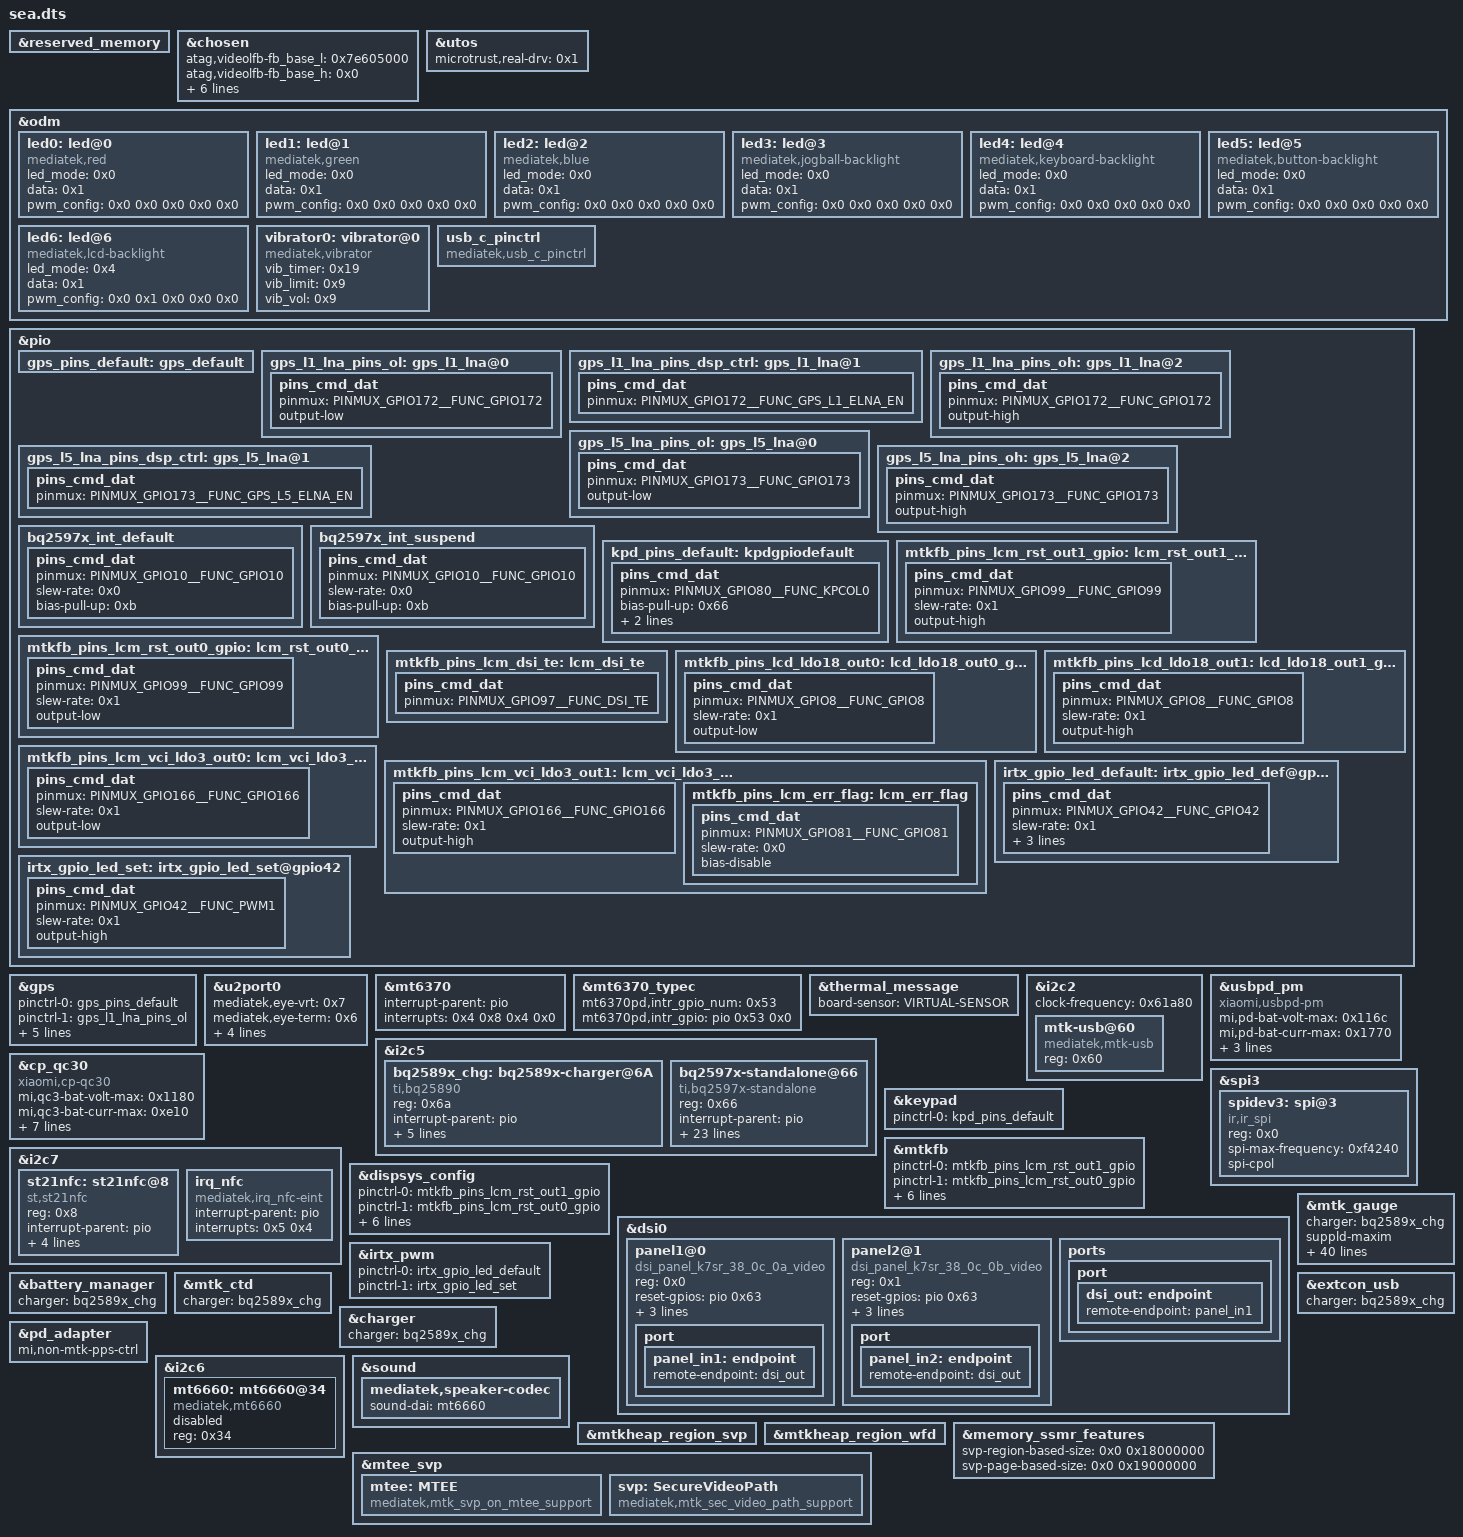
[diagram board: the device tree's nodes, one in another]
// SPDX-License-Identifier: GPL-2.0-only
/* Xiaomi Redmi Note 12S (sea / mt6781) Device Tree Overlay for Google Android Common Kernel 6.6 */

/dts-v1/;
/plugin/;

#include <dt-bindings/interrupt-controller/arm-gic.h>
#include <dt-bindings/interrupt-controller/irq.h>
#include <dt-bindings/pinctrl/mt6781-pinfunc.h>
#include <dt-bindings/gpio/gpio.h>
#include <dt-bindings/iio/mt635x-auxadc.h>

&reserved_memory {
};

&chosen {
    atag,videolfb-fb_base_l = <0x7e605000>;
    atag,videolfb-fb_base_h = <0x0>;
    atag,videolfb-islcmfound = <0x1>;
    atag,videolfb-islcm_inited = <0x0>;
    atag,videolfb-fps = <0x1770>;
    atag,videolfb-vramSize = <0x17e8000>;
    atag,videolfb-lcmname = "nt35695_fhd_dsi_cmd_truly_rt5081_drv";
};

&utos {
    microtrust,real-drv = <0x1>;
};

&odm {
    led0: led@0 {
        compatible = "mediatek,red";
        led_mode = <0x0>;
        data = <0x1>;
        pwm_config = <0x0 0x0 0x0 0x0 0x0>;
    };
    led1: led@1 {
        compatible = "mediatek,green";
        led_mode = <0x0>;
        data = <0x1>;
        pwm_config = <0x0 0x0 0x0 0x0 0x0>;
    };
    led2: led@2 {
        compatible = "mediatek,blue";
        led_mode = <0x0>;
        data = <0x1>;
        pwm_config = <0x0 0x0 0x0 0x0 0x0>;
    };
    led3: led@3 {
        compatible = "mediatek,jogball-backlight";
        led_mode = <0x0>;
        data = <0x1>;
        pwm_config = <0x0 0x0 0x0 0x0 0x0>;
    };
    led4: led@4 {
        compatible = "mediatek,keyboard-backlight";
        led_mode = <0x0>;
        data = <0x1>;
        pwm_config = <0x0 0x0 0x0 0x0 0x0>;
    };
    led5: led@5 {
        compatible = "mediatek,button-backlight";
        led_mode = <0x0>;
        data = <0x1>;
        pwm_config = <0x0 0x0 0x0 0x0 0x0>;
    };
    led6: led@6 {
        compatible = "mediatek,lcd-backlight";
        led_mode = <0x4>;
        data = <0x1>;
        pwm_config = <0x0 0x1 0x0 0x0 0x0>;
    };
    vibrator0: vibrator@0 {
        compatible = "mediatek,vibrator";
        vib_timer = <0x19>;
        vib_limit = <0x9>;
        vib_vol = <0x9>;
    };
    usb_c_pinctrl: usb_c_pinctrl {
        compatible = "mediatek,usb_c_pinctrl";
    };
};

&pio {
    gps_pins_default: gps_default {
    };
    gps_l1_lna_pins_ol: gps_l1_lna@0 {
        pins_cmd_dat {
            pinmux = <PINMUX_GPIO172__FUNC_GPIO172>;
            output-low;
        };
    };
    gps_l1_lna_pins_dsp_ctrl: gps_l1_lna@1 {
        pins_cmd_dat {
            pinmux = <PINMUX_GPIO172__FUNC_GPS_L1_ELNA_EN>;
        };
    };
    gps_l1_lna_pins_oh: gps_l1_lna@2 {
        pins_cmd_dat {
            pinmux = <PINMUX_GPIO172__FUNC_GPIO172>;
            output-high;
        };
    };
    gps_l5_lna_pins_ol: gps_l5_lna@0 {
        pins_cmd_dat {
            pinmux = <PINMUX_GPIO173__FUNC_GPIO173>;
            output-low;
        };
    };
    gps_l5_lna_pins_dsp_ctrl: gps_l5_lna@1 {
        pins_cmd_dat {
            pinmux = <PINMUX_GPIO173__FUNC_GPS_L5_ELNA_EN>;
        };
    };
    gps_l5_lna_pins_oh: gps_l5_lna@2 {
        pins_cmd_dat {
            pinmux = <PINMUX_GPIO173__FUNC_GPIO173>;
            output-high;
        };
    };
};

&gps {
    pinctrl-names = "default", "gps_l1_lna_disable", "gps_l1_lna_dsp_ctrl", "gps_l1_lna_enable", "gps_l5_lna_disable", "gps_l5_lna_dsp_ctrl", "gps_l5_lna_enable";
    pinctrl-0 = <&gps_pins_default>;
    pinctrl-1 = <&gps_l1_lna_pins_ol>;
    pinctrl-2 = <&gps_l1_lna_pins_dsp_ctrl>;
    pinctrl-3 = <&gps_l1_lna_pins_oh>;
    pinctrl-4 = <&gps_l5_lna_pins_ol>;
    pinctrl-5 = <&gps_l5_lna_pins_dsp_ctrl>;
    pinctrl-6 = <&gps_l5_lna_pins_oh>;
    status = "okay";
};

&u2port0 {
    mediatek,eye-vrt = <0x7>;
    mediatek,eye-term = <0x6>;
    mediatek,rev6 = <0x3>;
    mediatek,host-eye-vrt = <0x4>;
    mediatek,host-eye-term = <0x4>;
    mediatek,host-eye-rev6 = <0x1>;
};

&mt6370 {
    interrupt-parent = <&pio>;
    interrupts = <0x4 0x8 0x4 0x0>;
};

&mt6370_typec {
    mt6370pd,intr_gpio_num = <0x53>;
    mt6370pd,intr_gpio = <&pio 0x53 0x0>;
};

&thermal_message {
    board-sensor = "VIRTUAL-SENSOR";
};

&i2c2 {
    clock-frequency = <0x61a80>;
    mtk-usb@60 {
        compatible = "mediatek,mtk-usb";
        reg = <0x60>;
        status = "okay";
    };
};

&pio {
    bq2597x_int_default: bq2597x_int_default {
        pins_cmd_dat {
            pinmux = <PINMUX_GPIO10__FUNC_GPIO10>;
            slew-rate = <0x0>;
            bias-pull-up = <0xb>;
        };
    };
    bq2597x_int_suspend: bq2597x_int_suspend {
        pins_cmd_dat {
            pinmux = <PINMUX_GPIO10__FUNC_GPIO10>;
            slew-rate = <0x0>;
            bias-pull-up = <0xb>;
        };
    };
};

&i2c5 {
    status = "okay";
    bq2589x_chg: bq2589x-charger@6A {
        status = "okay";
        compatible = "ti,bq25890";
        reg = <0x6a>;
        interrupt-parent = <&pio>;
        interrupts = <0x1 0x2 0x1 0x0>;
        ti,irq-gpio = <&pio 0x1 0x0>;
        ti,bq2589x,charge-detect-enable;
        interrupt-names = "chr_stat";
        ti,CB1 = <&pio 0x2a 0x0>;
        ti,CB2 = <&pio 0x2b 0x0>;
    };
    bq2597x-standalone@66 {
        compatible = "ti,bq2597x-standalone";
        reg = <0x66>;
        interrupt-parent = <&pio>;
        interrupts = <0xa 0x2 0xa 0x0>;
        pinctrl-names = "chargerpump";
        pinctrl-0 = <&bq2597x_int_default &bq2597x_int_suspend>;
        ti,bq2597x,bat-ovp-alarm-disable;
        ti,bq2597x,bat-ucp-alarm-disable;
        ti,bq2597x,bat-ucp-disable;
        ti,bq2597x,bat-therm-disable;
        ti,bq2597x,bus-therm-disable;
        ti,bq2597x,die-therm-disable;
        ti,bq2597x,bat-ovp-threshold = <0x11ad>;
        ti,bq2597x,bat-ovp-alarm-threshold = <0x118a>;
        ti,bq2597x,bat-ocp-threshold = <0x1b58>;
        ti,bq2597x,bat-ocp-alarm-threshold = <0x1770>;
        ti,bq2597x,bus-ovp-threshold = <0x2ee0>;
        ti,bq2597x,bus-ovp-alarm-threshold = <0x2af8>;
        ti,bq2597x,bus-ocp-threshold = <0xea6>;
        ti,bq2597x,bus-ocp-alarm-threshold = <0xdac>;
        ti,bq2597x,bat-therm-threshold = <0x15>;
        ti,bq2597x,bus-therm-threshold = <0x15>;
        ti,bq2597x,die-therm-threshold = <0x91>;
        ti,bq2597x,ac-ovp-threshold = <0xe>;
        ti,bq2597x,sense-resistor-mohm = <0x5>;
        sc8551,ac-ovp-threshold = <0xd>;
    };
};

&usbpd_pm {
    compatible = "xiaomi,usbpd-pm";
    status = "okay";
    mi,pd-bat-volt-max = <0x116c>;
    mi,pd-bat-curr-max = <0x1770>;
    mi,pd-bus-volt-max = <0x2ee0>;
    mi,pd-bus-curr-max = <0xbb8>;
    mi,pd-non-ffc-bat-volt-max = <0x114e>;
};

&cp_qc30 {
    compatible = "xiaomi,cp-qc30";
    status = "okay";
    mi,qc3-bat-volt-max = <0x1180>;
    mi,qc3-bat-curr-max = <0xe10>;
    mi,qc3-bus-volt-max = <0x2ee0>;
    mi,qc3-bus-curr-max = <0x834>;
    mi,qc3-non-ffc-bat-volt-max = <0x1162>;
    mi,qc3-27w-bat-curr-max = <0x1518>;
    mi,qc3-27w-bus-curr-max = <0xa8c>;
    mi,qc3p-bat-curr-max = <0x1194>;
    mi,qc3p-bus-curr-max = <0x8fc>;
};

&spi3 {
    status = "okay";
    spidev3: spi@3 {
        compatible = "ir,ir_spi";
        reg = <0x0>;
        spi-max-frequency = <0xf4240>;
        spi-cpol;
    };
};

&i2c7 {
    st21nfc: st21nfc@8 {
        compatible = "st,st21nfc";
        reg = <0x8>;
        interrupt-parent = <&pio>;
        interrupts = <0x5 0x0>;
        reset-gpios = <&pio 0x1f 0x0>;
        irq-gpios = <&pio 0x5 0x0>;
        clkreq-gpios = <&pio 0x52 0x0>;
        status = "ok";
    };
    irq_nfc: irq_nfc {
        compatible = "mediatek,irq_nfc-eint";
        interrupt-parent = <&pio>;
        interrupts = <0x5 0x4>;
        status = "okay";
    };
};

&keypad {
    pinctrl-names = "default";
    pinctrl-0 = <&kpd_pins_default>;
};

&pio {
    kpd_pins_default: kpdgpiodefault {
        pins_cmd_dat {
            pinmux = <PINMUX_GPIO80__FUNC_KPCOL0>;
            bias-pull-up = <0x66>;
            input-enable;
            input-schmitt-enable;
        };
    };
};

&pio {
    mtkfb_pins_lcm_rst_out1_gpio: lcm_rst_out1_gpio {
        pins_cmd_dat {
            pinmux = <PINMUX_GPIO99__FUNC_GPIO99>;
            slew-rate = <0x1>;
            output-high;
        };
    };
    mtkfb_pins_lcm_rst_out0_gpio: lcm_rst_out0_gpio {
        pins_cmd_dat {
            pinmux = <PINMUX_GPIO99__FUNC_GPIO99>;
            slew-rate = <0x1>;
            output-low;
        };
    };
    mtkfb_pins_lcm_dsi_te: lcm_dsi_te {
        pins_cmd_dat {
            pinmux = <PINMUX_GPIO97__FUNC_DSI_TE>;
        };
    };
    mtkfb_pins_lcd_ldo18_out0: lcd_ldo18_out0_gpio {
        pins_cmd_dat {
            pinmux = <PINMUX_GPIO8__FUNC_GPIO8>;
            slew-rate = <0x1>;
            output-low;
        };
    };
    mtkfb_pins_lcd_ldo18_out1: lcd_ldo18_out1_gpio {
        pins_cmd_dat {
            pinmux = <PINMUX_GPIO8__FUNC_GPIO8>;
            slew-rate = <0x1>;
            output-high;
        };
    };
    mtkfb_pins_lcm_vci_ldo3_out0: lcm_vci_ldo3_out0_gpio {
        pins_cmd_dat {
            pinmux = <PINMUX_GPIO166__FUNC_GPIO166>;
            slew-rate = <0x1>;
            output-low;
        };
    };
    mtkfb_pins_lcm_vci_ldo3_out1: lcm_vci_ldo3_out1_gpio {
        pins_cmd_dat {
            pinmux = <PINMUX_GPIO166__FUNC_GPIO166>;
            slew-rate = <0x1>;
            output-high;
        };
        mtkfb_pins_lcm_err_flag: lcm_err_flag {
            pins_cmd_dat {
                pinmux = <PINMUX_GPIO81__FUNC_GPIO81>;
                slew-rate = <0x0>;
                bias-disable;
            };
        };
    };
};

&mtkfb {
    pinctrl-names = "lcm_rst_out1_gpio", "lcm_rst_out0_gpio", "mode_te_te", "lcd_ldo18_out1_gpio", "lcd_ldo18_out0_gpio", "lcm_vci_ldo3_out1_gpio", "lcm_vci_ldo3_out0_gpio", "err_flag_init";
    pinctrl-0 = <&mtkfb_pins_lcm_rst_out1_gpio>;
    pinctrl-1 = <&mtkfb_pins_lcm_rst_out0_gpio>;
    pinctrl-2 = <&mtkfb_pins_lcm_dsi_te>;
    pinctrl-3 = <&mtkfb_pins_lcd_ldo18_out1>;
    pinctrl-4 = <&mtkfb_pins_lcd_ldo18_out0>;
    pinctrl-7 = <&mtkfb_pins_lcm_vci_ldo3_out1>;
    pinctrl-8 = <&mtkfb_pins_lcm_vci_ldo3_out0>;
    pinctrl-9 = <&mtkfb_pins_lcm_err_flag>;
    status = "okay";
};

&dispsys_config {
    pinctrl-names = "lcm_rst_out1_gpio", "lcm_rst_out0_gpio", "mode_te_te", "lcd_ldo18_out1_gpio", "lcd_ldo18_out0_gpio", "lcm_vci_ldo3_out1_gpio", "lcm_vci_ldo3_out0_gpio", "err_flag_init";
    pinctrl-0 = <&mtkfb_pins_lcm_rst_out1_gpio>;
    pinctrl-1 = <&mtkfb_pins_lcm_rst_out0_gpio>;
    pinctrl-2 = <&mtkfb_pins_lcm_dsi_te>;
    pinctrl-3 = <&mtkfb_pins_lcd_ldo18_out1>;
    pinctrl-4 = <&mtkfb_pins_lcd_ldo18_out0>;
    pinctrl-7 = <&mtkfb_pins_lcm_vci_ldo3_out1>;
    pinctrl-8 = <&mtkfb_pins_lcm_vci_ldo3_out0>;
    pinctrl-9 = <&mtkfb_pins_lcm_err_flag>;
    status = "okay";
};

&dsi0 {
    status = "okay";
    #address-cells = <0x1>;
    #size-cells = <0x0>;
    panel1@0 {
        compatible = "dsi_panel_k7sr_38_0c_0a_video";
        reg = <0x0>;
        reset-gpios = <&pio 0x63 0x0>;
        vci-gpios = <&pio 0xa6 0x0>;
        vddi-gpios = <&pio 0x8 0x0>;
        mi,esd-err-irq-gpio = <&pio 0x51 0x2002>;
        pinctrl-names = "default";
        port {
            panel_in1: endpoint {
                remote-endpoint = <&dsi_out>;
            };
        };
    };
    panel2@1 {
        compatible = "dsi_panel_k7sr_38_0c_0b_video";
        reg = <0x1>;
        reset-gpios = <&pio 0x63 0x0>;
        vci-gpios = <&pio 0xa6 0x0>;
        vddi-gpios = <&pio 0x8 0x0>;
        mi,esd-err-irq-gpio = <&pio 0x51 0x2001>;
        pinctrl-names = "default";
        port {
            panel_in2: endpoint {
                remote-endpoint = <&dsi_out>;
            };
        };
    };
    ports {
        port {
            dsi_out: endpoint {
                remote-endpoint = <&panel_in1>;
            };
        };
    };
};

&irtx_pwm {
    pinctrl-names = "irtx_gpio_led_default", "irtx_gpio_led_set";
    pinctrl-0 = <&irtx_gpio_led_default>;
    pinctrl-1 = <&irtx_gpio_led_set>;
    status = "okay";
};

&pio {
    irtx_gpio_led_default: irtx_gpio_led_def@gpio42 {
        pins_cmd_dat {
            pinmux = <PINMUX_GPIO42__FUNC_GPIO42>;
            slew-rate = <0x1>;
            bias-disable;
            output-low;
            input-schmitt-enable = <0x0>;
        };
    };
    irtx_gpio_led_set: irtx_gpio_led_set@gpio42 {
        pins_cmd_dat {
            pinmux = <PINMUX_GPIO42__FUNC_PWM1>;
            slew-rate = <0x1>;
            output-high;
        };
    };
};

&mtk_gauge {
    charger = <&bq2589x_chg>;
    suppld-maxim;
    battery0_profile_t0_num = <0x64>;
    battery0_profile_t0_col = <0x3>;
    battery0_profile_t0 = <0x0 0xac94 0x1e0 0x1fd 0xabfb 0x1dc 0x3fa 0xab78 0x1ec 0x5f7 0xaafe 0x1f4 0x7f4 0xaa87 0x1ea 0x9f0 0xaa15 0x1e7 0xbed 0xa9ae 0x20b 0xdea 0xa937 0x1f6 0xfe7 0xa8c0 0x1f4 0x11e4 0xa849 0x1f4 0x13e1 0xa7d3 0x1f4 0x15de 0xa75c 0x1fc 0x17db 0xa6e3 0x209 0x19d8 0xa664 0x1f5 0x1bd4 0xa5ee 0x20a 0x1dd1 0xa570 0x1fb 0x1fce 0xa4f0 0x1f4 0x21cb 0xa475 0x1f4 0x23c8 0xa3fe 0x1fb 0x25c5 0xa386 0x20d 0x27c2 0xa30f 0x20d 0x29bf 0xa290 0x1f8 0x2bbc 0xa21e 0x205 0x2db8 0xa1ab 0x21a 0x2fb5 0xa134 0x21d 0x31b2 0xa0bf 0x20d 0x33af 0xa050 0x20d 0x35ac 0x9fda 0x20d 0x37a9 0x9f72 0x220 0x39a6 0x9f06 0x226 0x3ba3 0x9e9d 0x232 0x3da0 0x9e34 0x237 0x3f9c 0x9dc9 0x22a 0x4199 0x9d6b 0x23f 0x4396 0x9d06 0x23f 0x4593 0x9ca7 0x251 0x4790 0x9c4a 0x258 0x498d 0x9bf0 0x26c 0x4b8a 0x9b96 0x284 0x4d87 0x9b32 0x276 0x4f84 0x9ad4 0x2a0 0x5180 0x9a67 0x2a3 0x537d 0x99df 0x273 0x557a 0x994f 0x240 0x5777 0x98cc 0x215 0x5974 0x9864 0x1f4 0x5b71 0x980f 0x1f4 0x5d6e 0x97c3 0x1f4 0x5f6b 0x9785 0x206 0x6168 0x9744 0x20d 0x6364 0x9704 0x20d 0x6561 0x96c9 0x20d 0x675e 0x968e 0x20a 0x695b 0x9652 0x1f5 0x6b58 0x961e 0x1f4 0x6d55 0x95eb 0x205 0x6f52 0x95be 0x20d 0x714f 0x958f 0x204 0x734c 0x955f 0x1fa 0x7548 0x9534 0x20d 0x7745 0x950a 0x20d 0x7942 0x94e7 0x20d 0x7b3f 0x94bf 0x20d 0x7d3c 0x9499 0x219 0x7f39 0x9477 0x226 0x8136 0x9455 0x22a 0x8333 0x9434 0x23f 0x8530 0x9412 0x23f 0x872c 0x93e9 0x251 0x8929 0x93a2 0x22e 0x8b26 0x9352 0x20d 0x8d23 0x930a 0x207 0x8f20 0x92d1 0x1f7 0x911d 0x92a7 0x20c 0x931a 0x9274 0x20d 0x9517 0x923b 0x1fd 0x9714 0x9209 0x200 0x9910 0x91df 0x204 0x9b0d 0x91b6 0x1f9 0x9d0a 0x9193 0x20c 0x9f07 0x9158 0x1f7 0xa104 0x9115 0x1f4 0xa301 0x90d7 0x203 0xa4fe 0x909c 0x20d 0xa6fb 0x9058 0x20d 0xa8f8 0x9008 0x20a 0xaaf4 0x8fd6 0x1f5 0xacf1 0x8fcc 0x209 0xaeee 0x8fbd 0x1fc 0xb0eb 0x8fb1 0x20e 0xb2e8 0x8f9d 0x226 0xb4e5 0x8f66 0x226 0xb6e2 0x8edf 0x226 0xb8df 0x8d6a 0x226 0xbadc 0x8b71 0x24d 0xbcd8 0x88d6 0x296 0xbed5 0x851d 0x31a 0xc0d2 0x7e46 0x991 0xc2cf 0x7084 0x7db 0xc4cc 0x6fa4 0x5dc>;
    battery0_profile_t1_num = <0x64>;
    battery0_profile_t1_col = <0x3>;
    battery0_profile_t1 = <0x0 0xacbc 0x30c 0x1fd 0xac3d 0x308 0x3fa 0xabcb 0x318 0x5f7 0xab5d 0x312 0x7f4 0xaaf3 0x311 0x9f0 0xaa8b 0x31a 0xbed 0xaa1c 0x307 0xdea 0xa9ae 0x307 0xfe7 0xa940 0x307 0x11e4 0xa8cb 0x307 0x13e1 0xa855 0x307 0x15de 0xa7db 0x2ff 0x17db 0xa75d 0x2f2 0x19d8 0xa6e6 0x306 0x1bd4 0xa667 0x2f1 0x1dd1 0xa5ef 0x300 0x1fce 0xa572 0x307 0x21cb 0xa4f3 0x2fd 0x23c8 0xa476 0x2f5 0x25c5 0xa3fe 0x307 0x27c2 0xa387 0x307 0x29bf 0xa308 0x307 0x2bbc 0xa296 0x318 0x2db8 0xa223 0x320 0x2fb5 0xa1ac 0x320 0x31b2 0xa135 0x320 0x33af 0xa0bf 0x322 0x35ac 0xa051 0x337 0x37a9 0x9fe3 0x339 0x39a6 0x9f74 0x339 0x3ba3 0x9f06 0x345 0x3da0 0x9e9b 0x352 0x3f9c 0x9e35 0x356 0x4199 0x9dcf 0x36b 0x4396 0x9d6a 0x380 0x4593 0x9d0b 0x396 0x4790 0x9ca8 0x3ab 0x498d 0x9c46 0x3c0 0x4b8a 0x9be6 0x3d5 0x4d87 0x9b81 0x3e8 0x4f84 0x9b1b 0x3e8 0x5180 0x9aad 0x3d4 0x537d 0x9a32 0x3af 0x557a 0x99ae 0x378 0x5777 0x992d 0x341 0x5974 0x98ba 0x317 0x5b71 0x9855 0x2ed 0x5d6e 0x9800 0x2d8 0x5f6b 0x97b3 0x2d5 0x6168 0x976c 0x2c7 0x6364 0x972c 0x2c7 0x6561 0x96f1 0x2d5 0x675e 0x96b7 0x2d8 0x695b 0x9684 0x2ed 0x6b58 0x9648 0x2d9 0x6d55 0x961a 0x2e6 0x6f52 0x95ea 0x2e1 0x714f 0x95bb 0x2de 0x734c 0x958e 0x2ee 0x7548 0x955c 0x2ee 0x7745 0x9532 0x2ee 0x7942 0x950f 0x2ee 0x7b3f 0x94ed 0x2fd 0x7d3c 0x94c7 0x2fb 0x7f39 0x94a3 0x2fe 0x8136 0x9487 0x320 0x8333 0x9466 0x320 0x8530 0x9444 0x320 0x872c 0x9422 0x320 0x8929 0x9400 0x320 0x8b26 0x93d6 0x316 0x8d23 0x93a5 0x301 0x8f20 0x937b 0x2ee 0x911d 0x9351 0x2ee 0x931a 0x931e 0x2da 0x9517 0x92eb 0x2c5 0x9714 0x92bd 0x2bc 0x9910 0x9296 0x2c5 0x9b0d 0x9274 0x2d5 0x9d0a 0x9252 0x2d5 0x9f07 0x921f 0x2d5 0xa104 0x91e5 0x2c3 0xa301 0x91a9 0x2cb 0xa4fe 0x916e 0x2d5 0xa6fb 0x9130 0x2d5 0xa8f8 0x90e9 0x2d8 0xaaf4 0x9095 0x2ed 0xacf1 0x9069 0x2d9 0xaeee 0x9053 0x2d5 0xb0eb 0x9047 0x2e2 0xb2e8 0x903a 0x301 0xb4e5 0x9025 0x320 0xb6e2 0x8ffb 0x322 0xb8df 0x8f84 0x337 0xbadc 0x8e15 0x339 0xbcd8 0x8c12 0x368 0xbed5 0x895e 0x3b3 0xc0d2 0x8571 0x450 0xc2cf 0x7e79 0x8d4 0xc4cc 0x726a 0xccb>;
    battery0_profile_t2_num = <0x64>;
    battery0_profile_t2_col = <0x3>;
    battery0_profile_t2 = <0x0 0xacc6 0x596 0x1fd 0xac3e 0x592 0x3fa 0xabcb 0x5a2 0x5f7 0xab5d 0x59c 0x7f4 0xaaf3 0x591 0x9f0 0xaa8d 0x58b 0xbed 0xaa26 0x576 0xdea 0xa9b8 0x561 0xfe7 0xa94a 0x573 0x11e4 0xa8d5 0x558 0x13e1 0xa85f 0x546 0x15de 0xa7e5 0x536 0x17db 0xa767 0x518 0x19d8 0xa6f0 0x52c 0x1bd4 0xa671 0x517 0x1dd1 0xa5f2 0x514 0x1fce 0xa578 0x522 0x21cb 0xa4fd 0x523 0x23c8 0xa480 0x51b 0x25c5 0xa406 0x52a 0x27c2 0xa387 0x515 0x29bf 0xa310 0x529 0x2bbc 0xa299 0x52d 0x2db8 0xa223 0x52d 0x2fb5 0xa1ac 0x536 0x31b2 0xa137 0x54c 0x33af 0xa0c8 0x55f 0x35ac 0xa052 0x55f 0x37a9 0x9fe3 0x572 0x39a6 0x9f74 0x578 0x3ba3 0x9f0b 0x584 0x3da0 0x9ea5 0x5a0 0x3f9c 0x9e3e 0x5c3 0x4199 0x9dcf 0x5c3 0x4396 0x9d61 0x5d8 0x4593 0x9cfa 0x5ee 0x4790 0x9c94 0x5e7 0x498d 0x9c32 0x5e6 0x4b8a 0x9bd2 0x5f5 0x4d87 0x9b6d 0x5f5 0x4f84 0x9b07 0x5f5 0x5180 0x9a89 0x5ba 0x537d 0x9a0a 0x57a 0x557a 0x9986 0x52e 0x5777 0x9908 0x4ea 0x5974 0x989c 0x4c0 0x5b71 0x9837 0x496 0x5d6e 0x97e2 0x481 0x5f6b 0x979c 0x47e 0x6168 0x9758 0x47e 0x6364 0x9714 0x47e 0x6561 0x96d3 0x47e 0x675e 0x9699 0x47e 0x695b 0x9666 0x47e 0x6b58 0x9632 0x493 0x6d55 0x95f8 0x486 0x6f52 0x95c8 0x48b 0x714f 0x9599 0x497 0x734c 0x9569 0x497 0x7548 0x953e 0x497 0x7745 0x9514 0x497 0x7942 0x94f1 0x4aa 0x7b3f 0x94c9 0x4b0 0x7d3c 0x94a3 0x4b0 0x7f39 0x9481 0x4b8 0x8136 0x945f 0x4c9 0x8333 0x943e 0x4c9 0x8530 0x9424 0x4de 0x872c 0x9404 0x4d0 0x8929 0x93e7 0x4d7 0x8b26 0x93ca 0x4d8 0x8d23 0x93aa 0x4c9 0x8f20 0x9390 0x4c6 0x911d 0x936e 0x4b1 0x931a 0x934c 0x4b0 0x9517 0x9324 0x4b0 0x9714 0x92f4 0x4a4 0x9910 0x92c8 0x4a0 0x9b0d 0x92a5 0x4b0 0x9d0a 0x927a 0x4b1 0x9f07 0x9250 0x4c6 0xa104 0x920f 0x4db 0xa301 0x91cb 0x4e2 0xa4fe 0x918c 0x4ed 0xa6fb 0x914e 0x509 0xa8f8 0x9106 0x530 0xaaf4 0x90a9 0x545 0xacf1 0x907d 0x55b 0xaeee 0x9060 0x581 0xb0eb 0x904b 0x5b9 0xb2e8 0x9037 0x5ef 0xb4e5 0x9018 0x631 0xb6e2 0x8fe7 0x6b4 0xb8df 0x8f70 0x75e 0xbadc 0x8e18 0x7a6 0xbcd8 0x8c16 0x824 0xbed5 0x8955 0x952 0xc0d2 0x854d 0xbfa 0xc2cf 0x7e49 0x12cc 0xc4cc 0x7152 0x9dd>;
    battery0_profile_t3_num = <0x64>;
    battery0_profile_t3_col = <0x3>;
    battery0_profile_t3 = <0x0 0xace4 0x834 0x1fd 0xac54 0x834 0x3fa 0xabd2 0x9d6 0x5f7 0xab5d 0xaa7 0x7f4 0xaaf3 0xab4 0x9f0 0xaa8b 0xa99 0xbed 0xaa1d 0xa71 0xdea 0xa9b8 0xa5c 0xfe7 0xa942 0xa1f 0x11e4 0xa8d2 0xa0f 0x13e1 0xa85f 0xa03 0x15de 0xa7e5 0x9ee 0x17db 0xa767 0x9dd 0x19d8 0xa6f0 0x9dc 0x1bd4 0xa67a 0x9c7 0x1dd1 0xa5fc 0x9b2 0x1fce 0xa57c 0x99d 0x21cb 0xa501 0x992 0x23c8 0xa48a 0x984 0x25c5 0xa412 0x95d 0x27c2 0xa39b 0x948 0x29bf 0xa324 0x947 0x2bbc 0xa2a7 0x925 0x2db8 0xa232 0x922 0x2fb5 0xa1c0 0x925 0x31b2 0xa149 0x915 0x33af 0xa0d3 0x915 0x35ac 0xa065 0x915 0x37a9 0x9fef 0x902 0x39a6 0x9f84 0x90b 0x3ba3 0x9f1f 0x92c 0x3da0 0x9eb6 0x94f 0x3f9c 0x9e46 0x960 0x4199 0x9dcf 0x960 0x4396 0x9d61 0x975 0x4593 0x9cec 0x956 0x4790 0x9c7b 0x939 0x498d 0x9c10 0x924 0x4b8a 0x9ba8 0x909 0x4d87 0x9b3a 0x8de 0x4f84 0x9acb 0x8b4 0x5180 0x9a55 0x889 0x537d 0x99df 0x84f 0x557a 0x9968 0x803 0x5777 0x98f8 0x7c8 0x5974 0x9892 0x7ae 0x5b71 0x982d 0x784 0x5d6e 0x97e1 0x76f 0x5f6b 0x978d 0x75a 0x6168 0x9744 0x753 0x6364 0x9704 0x75e 0x6561 0x96c6 0x765 0x675e 0x9685 0x756 0x695b 0x9652 0x76b 0x6b58 0x9616 0x76c 0x6d55 0x95e1 0x77d 0x6f52 0x95ae 0x785 0x714f 0x957f 0x78e 0x734c 0x9552 0x79e 0x7548 0x9520 0x79e 0x7745 0x94f6 0x79e 0x7942 0x94d3 0x7c5 0x7b3f 0x94ab 0x7d0 0x7d3c 0x9485 0x7dc 0x7f39 0x9463 0x7f1 0x8136 0x9441 0x802 0x8333 0x9420 0x802 0x8530 0x9406 0x817 0x872c 0x93e6 0x81b 0x8929 0x93cf 0x81b 0x8b26 0x93be 0x82f 0x8d23 0x93ad 0x85a 0x8f20 0x939b 0x87f 0x911d 0x9382 0x87f 0x931a 0x9360 0x8a7 0x9517 0x933e 0x8c1 0x9714 0x9317 0x8e3 0x9910 0x92f0 0x916 0x9b0d 0x92cb 0x955 0x9d0a 0x9298 0x996 0x9f07 0x9265 0x9eb 0xa104 0x9223 0xa2d 0xa301 0x91df 0xa8a 0xa4fe 0x919c 0xaf4 0xa6fb 0x9155 0xb65 0xa8f8 0x9107 0xbe4 0xaaf4 0x90b3 0xc63 0xacf1 0x9076 0xd0b 0xaeee 0x9048 0xdc6 0xb0eb 0x9023 0xeae 0xb2e8 0x9001 0xfcc 0xb4e5 0x8fd8 0x1121 0xb6e2 0x8f95 0x12be 0xb8df 0x8f0e 0x14bb 0xbadc 0x8df2 0x16de 0xbcd8 0x8c34 0x19f0 0xbed5 0x89bb 0x1f51 0xc0d2 0x864d 0x2a26 0xc2cf 0x8163 0x3210 0xc4cc 0x7828 0x1b58>;
    battery0_profile_t4_num = <0x64>;
    battery0_profile_t4_col = <0x3>;
    battery0_profile_t4 = <0x0 0xacda 0x13d8 0x1fd 0xac1f 0x13d4 0x3fa 0xab88 0x13e4 0x5f7 0xab02 0x13de 0x7f4 0xaa83 0x13c9 0x9f0 0xaa04 0x13c6 0xbed 0xa986 0x13e8 0xdea 0xa90f 0x13bd 0xfe7 0xa898 0x137f 0x11e4 0xa821 0x1310 0x13e1 0xa7ab 0x129d 0x15de 0xa734 0x123b 0x17db 0xa6bd 0x11f4 0x19d8 0xa646 0x11df 0x1bd4 0xa5c7 0x11df 0x1dd1 0xa54f 0x11cd 0x1fce 0xa4d2 0x11b8 0x21cb 0xa45c 0x11ad 0x23c8 0xa3e7 0x119f 0x25c5 0xa369 0x117b 0x27c2 0xa2fb 0x117b 0x29bf 0xa284 0x1166 0x2bbc 0xa20d 0x1140 0x2db8 0xa19c 0x1123 0x2fb5 0xa12a 0x10fb 0x31b2 0xa0b5 0x10cc 0x33af 0xa047 0x10cc 0x35ac 0x9fd9 0x10cc 0x37a9 0x9f72 0x1105 0x39a6 0x9f00 0x1117 0x3ba3 0x9e89 0x1123 0x3da0 0x9e10 0x1128 0x3f9c 0x9d8f 0x110f 0x4199 0x9d07 0x10e5 0x4396 0x9c88 0x10ba 0x4593 0x9c10 0x1090 0x4790 0x9b99 0x1066 0x498d 0x9b26 0x103b 0x4b8a 0x9aba 0x101d 0x4d87 0x9a54 0x101b 0x4f84 0x99e5 0x1005 0x5180 0x9977 0xfdc 0x537d 0x990f 0xfe2 0x557a 0x98aa 0xfdf 0x5777 0x9847 0xfca 0x5974 0x97ee 0xfbe 0x5b71 0x97a1 0xfd2 0x5d6e 0x974c 0xfd2 0x5f6b 0x9706 0xfd2 0x6168 0x96c2 0xfd2 0x6364 0x967e 0xfdd 0x6561 0x9640 0xff2 0x675e 0x960c 0x1007 0x695b 0x95d0 0x101c 0x6b58 0x959c 0x1032 0x6d55 0x9569 0x1047 0x6f52 0x9536 0x105c 0x714f 0x9507 0x1071 0x734c 0x94dd 0x1087 0x7548 0x94b3 0x109e 0x7745 0x9491 0x10c8 0x7942 0x946f 0x10f3 0x7b3f 0x9453 0x111d 0x7d3c 0x943a 0x1147 0x7f39 0x9421 0x117a 0x8136 0x9409 0x11b9 0x8333 0x93f8 0x11f9 0x8530 0x93e7 0x124e 0x872c 0x93d6 0x12b4 0x8929 0x93bf 0x131e 0x8b26 0x93a6 0x1388 0x8d23 0x938c 0x13f9 0x8f20 0x9373 0x147b 0x911d 0x935a 0x150f 0x931a 0x9338 0x15b7 0x9517 0x9310 0x1661 0x9714 0x92e5 0x1717 0x9910 0x92b8 0x17d6 0x9b0d 0x9283 0x1899 0x9d0a 0x9247 0x196e 0x9f07 0x920c 0x1a57 0xa104 0x91c9 0x1b53 0xa301 0x9185 0x1c60 0xa4fe 0x913d 0x1d74 0xa6fb 0x90f1 0x1e9c 0xa8f8 0x90a7 0x1ff6 0xaaf4 0x906c 0x2173 0xacf1 0x9030 0x2306 0xaeee 0x9002 0x24fd 0xb0eb 0x8fd2 0x2771 0xb2e8 0x8f97 0x2a6a 0xb4e5 0x8f48 0x2e06 0xb6e2 0x8ecf 0x3289 0xb8df 0x8df3 0x3840 0xbadc 0x8ca2 0x3fdc 0xbcd8 0x8b01 0x482d 0xbed5 0x88e9 0x44dc 0xc0d2 0x8589 0x3c6f 0xc2cf 0x850c 0x3bab 0xc4cc 0x850c 0x3bab>;
    battery1_profile_t0_num = <0x64>;
    battery1_profile_t0_col = <0x3>;
    battery1_profile_t0 = <0x0 0xac9e 0x1e0 0x1fe 0xac05 0x1dc 0x3fc 0xab81 0x1ec 0x5f9 0xab07 0x1f4 0x7f7 0xaa90 0x1ea 0x9f5 0xaa1c 0x1e1 0xbf3 0xa9ad 0x1f4 0xdf1 0xa93f 0x1f4 0xfee 0xa8c8 0x1f4 0x11ec 0xa851 0x1f4 0x13ea 0xa7da 0x1f4 0x15e8 0xa764 0x1f4 0x17e6 0xa6eb 0x1f4 0x19e3 0xa66b 0x1f4 0x1be1 0xa5ee 0x1f4 0x1ddf 0xa576 0x206 0x1fdd 0xa4f9 0x1ff 0x21db 0xa47e 0x1f4 0x23d8 0xa407 0x1fb 0x25d6 0xa38f 0x20a 0x27d4 0xa310 0x1f5 0x29d2 0xa298 0x209 0x2bd0 0xa221 0x20d 0x2dcd 0xa1b0 0x20d 0x2fcb 0xa13d 0x20d 0x31c9 0xa0c9 0x213 0x33c7 0xa05a 0x226 0x35c5 0x9fec 0x226 0x37c2 0x9f76 0x213 0x39c0 0x9f0b 0x21d 0x3bbe 0x9ea0 0x226 0x3dbc 0x9e35 0x226 0x3fba 0x9dd1 0x22a 0x41b7 0x9d73 0x23f 0x43b5 0x9d0d 0x23f 0x45b3 0x9caf 0x251 0x47b1 0x9c51 0x266 0x49af 0x9bf4 0x271 0x4bac 0x9b96 0x278 0x4daa 0x9b39 0x28d 0x4fa8 0x9adb 0x2a2 0x51a6 0x9a6f 0x2a3 0x53a4 0x99e7 0x282 0x55a1 0x9957 0x24b 0x579f 0x98d4 0x21d 0x599d 0x986c 0x208 0x5b9b 0x9817 0x1f4 0x5d99 0x97cb 0x1f4 0x5f96 0x9786 0x207 0x6194 0x9742 0x1fe 0x6392 0x9703 0x1f4 0x6590 0x96c7 0x1f4 0x678d 0x968d 0x1f8 0x698b 0x965a 0x20d 0x6b89 0x9627 0x20d 0x6d87 0x95f4 0x20d 0x6f85 0x95c1 0x20d 0x7182 0x9592 0x20d 0x7380 0x9568 0x20d 0x757e 0x953d 0x20d 0x777c 0x9513 0x20d 0x797a 0x94e8 0x20d 0x7b77 0x94c4 0x21d 0x7d75 0x94a2 0x226 0x7f73 0x9480 0x22f 0x8171 0x945e 0x23f 0x836f 0x943c 0x23f 0x856c 0x9411 0x23f 0x876a 0x93e7 0x23f 0x8968 0x93a6 0x222 0x8b66 0x9355 0x202 0x8d64 0x930b 0x1fb 0x8f61 0x92da 0x20d 0x915f 0x92af 0x20d 0x935d 0x927c 0x20d 0x955b 0x9243 0x1fc 0x9759 0x9212 0x201 0x9956 0x91e7 0x204 0x9b54 0x91bf 0x1fa 0x9d52 0x919c 0x20d 0x9f50 0x9169 0x20d 0xa14e 0x9126 0x20d 0xa34b 0x90e2 0x1fd 0xa549 0x90a3 0x200 0xa747 0x905e 0x205 0xa945 0x9010 0x1f4 0xab43 0x8fde 0x1f5 0xad40 0x8fd5 0x20a 0xaf3e 0x8fc6 0x20d 0xb13c 0x8fb5 0x20d 0xb33a 0x8fa4 0x222 0xb538 0x8f78 0x23f 0xb735 0x8eef 0x23c 0xb933 0x8d93 0x227 0xbb31 0x8b9b 0x24f 0xbd2f 0x8913 0x289 0xbf2d 0x8583 0x314 0xc12a 0x7ef5 0x895 0xc328 0x71f6 0xbf9 0xc526 0x6fae 0x60e>;
    battery1_profile_t1_num = <0x64>;
    battery1_profile_t1_col = <0x3>;
    battery1_profile_t1 = <0x0 0xacc6 0x320 0x1fe 0xac47 0x320 0x3fc 0xabce 0x320 0x5f9 0xab62 0x320 0x7f7 0xaaf8 0x320 0x9f5 0xaa8c 0x320 0xbf3 0xaa25 0x320 0xdf1 0xa9b7 0x320 0xfee 0xa940 0x30c 0x11ec 0xa8c9 0x307 0x13ea 0xa852 0x307 0x15e8 0xa7dc 0x307 0x17e6 0xa765 0x30c 0x19e3 0xa6ed 0x31f 0x1be1 0xa670 0x30a 0x1ddf 0xa5f1 0x307 0x1fdd 0xa577 0x315 0x21db 0xa4fc 0x315 0x23d8 0xa47f 0x30e 0x25d6 0xa408 0x320 0x27d4 0xa391 0x320 0x29d2 0xa312 0x320 0x2bd0 0xa299 0x320 0x2dcd 0xa222 0x320 0x2fcb 0xa1af 0x329 0x31c9 0xa13f 0x339 0x33c7 0xa0c8 0x339 0x35c5 0xa05a 0x339 0x37c2 0x9fe4 0x339 0x39c0 0x9f73 0x339 0x3bbe 0x9f09 0x345 0x3dbc 0x9ea3 0x35a 0x3fba 0x9e3c 0x36b 0x41b7 0x9dcd 0x36c 0x43b5 0x9d67 0x381 0x45b3 0x9d09 0x396 0x47b1 0x9cab 0x3ba 0x49af 0x9c49 0x3cf 0x4bac 0x9be6 0x3d6 0x4daa 0x9b88 0x3eb 0x4fa8 0x9b22 0x400 0x51a6 0x9ab5 0x401 0x53a4 0x9a3a 0x3d0 0x55a1 0x99b1 0x384 0x579f 0x992b 0x338 0x599d 0x98b8 0x302 0x5b9b 0x9853 0x2ed 0x5d99 0x97fe 0x2d7 0x5f96 0x97b8 0x2e8 0x6194 0x9774 0x2ee 0x6392 0x9730 0x2e3 0x6590 0x96ef 0x2d5 0x678d 0x96b5 0x2d9 0x698b 0x9682 0x2ee 0x6b89 0x964f 0x2ee 0x6d87 0x961c 0x2ee 0x6f85 0x95e9 0x2ee 0x7182 0x95ba 0x2ee 0x7380 0x9590 0x2f4 0x757e 0x9565 0x307 0x777c 0x953b 0x307 0x797a 0x9510 0x2f3 0x7b77 0x94ec 0x2fe 0x7d75 0x94ca 0x307 0x7f73 0x94a8 0x310 0x8171 0x9486 0x320 0x836f 0x9464 0x320 0x856c 0x9442 0x320 0x876a 0x9421 0x320 0x8968 0x93ff 0x320 0x8b66 0x93d9 0x315 0x8d64 0x93ab 0x300 0x8f61 0x937a 0x2eb 0x915f 0x934f 0x2d6 0x935d 0x931c 0x2d5 0x955b 0x92f0 0x2d5 0x9759 0x92c1 0x2c8 0x9956 0x9295 0x2c5 0x9b54 0x9273 0x2d5 0x9d52 0x9250 0x2d7 0x9f50 0x9226 0x2ec 0xa14e 0x91ec 0x2db 0xa34b 0x91aa 0x2d5 0xa549 0x9170 0x2e1 0xa747 0x9136 0x2ee 0xa945 0x90ed 0x2ea 0xab43 0x9091 0x2d5 0xad40 0x9066 0x2d5 0xaf3e 0x9052 0x2d5 0xb13c 0x9046 0x2e3 0xb33a 0x903a 0x2f8 0xb538 0x9026 0x314 0xb735 0x9001 0x33c 0xb933 0x8f92 0x351 0xbb31 0x8e1e 0x33e 0xbd2f 0x8c21 0x36a 0xbf2d 0x8975 0x3b6 0xc12a 0x8591 0x451 0xc328 0x7e79 0x947 0xc526 0x726a 0xce4>;
    battery1_profile_t2_num = <0x64>;
    battery1_profile_t2_col = <0x3>;
    battery1_profile_t2 = <0x0 0xacc6 0x564 0x1fe 0xac3e 0x560 0x3fc 0xabcb 0x55f 0x5f9 0xab62 0x56d 0x7f7 0xaaf8 0x564 0x9f5 0xaa8c 0x546 0xbf3 0xaa25 0x544 0xdf1 0xa9b7 0x52e 0xfee 0xa948 0x52d 0x11ec 0xa8d3 0x51d 0x13ea 0xa85c 0x514 0x15e8 0xa7e6 0x50b 0x17e6 0xa76d 0x4fb 0x19e3 0xa6ed 0x4fa 0x1be1 0xa670 0x4e5 0x1ddf 0xa5f8 0x4f4 0x1fdd 0xa57b 0x4fb 0x21db 0xa500 0x4fb 0x23d8 0xa486 0x4fb 0x25d6 0xa408 0x4fe 0x27d4 0xa391 0x513 0x29d2 0xa312 0x4ff 0x2bd0 0xa299 0x50c 0x2dcd 0xa222 0x514 0x2fcb 0xa1af 0x51d 0x31c9 0xa13f 0x52d 0x33c7 0xa0c8 0x52d 0x35c5 0xa051 0x52d 0x37c2 0x9fe1 0x540 0x39c0 0x9f73 0x546 0x3bbe 0x9f09 0x552 0x3dbc 0x9ea3 0x577 0x3fba 0x9e3c 0x5aa 0x41b7 0x9dcd 0x5ab 0x43b5 0x9d67 0x5d6 0x45b3 0x9cfa 0x5ca 0x47b1 0x9c91 0x5c3 0x49af 0x9c30 0x5ce 0x4bac 0x9bd2 0x5e3 0x4daa 0x9b72 0x5f2 0x4fa8 0x9b04 0x5dd 0x51a6 0x9a8f 0x5b4 0x53a4 0x9a0c 0x569 0x55a1 0x9989 0x514 0x579f 0x9910 0x4d0 0x599d 0x98a4 0x4ab 0x5b9b 0x983f 0x496 0x5d99 0x97ea 0x480 0x5f96 0x979c 0x46b 0x6194 0x9756 0x474 0x6392 0x9712 0x473 0x6590 0x96d1 0x465 0x678d 0x9697 0x465 0x698b 0x9664 0x465 0x6b89 0x9631 0x47a 0x6d87 0x95fe 0x47e 0x6f85 0x95cb 0x47e 0x7182 0x9598 0x474 0x7380 0x9568 0x46b 0x757e 0x953e 0x480 0x777c 0x951c 0x496 0x797a 0x94f2 0x497 0x7b77 0x94c8 0x497 0x7d75 0x94a2 0x497 0x7f73 0x9484 0x4a8 0x8171 0x9466 0x4c4 0x836f 0x943d 0x4b1 0x856c 0x9423 0x4c6 0x876a 0x9403 0x4b7 0x8968 0x93e7 0x4be 0x8b66 0x93c9 0x4be 0x8d64 0x93aa 0x4b0 0x8f61 0x938f 0x4ad 0x915f 0x936d 0x498 0x935d 0x934b 0x497 0x955b 0x931c 0x475 0x9759 0x92ee 0x472 0x9956 0x92c3 0x47e 0x9b54 0x929b 0x47e 0x9d52 0x9278 0x482 0x9f50 0x924e 0x4ac 0xa14e 0x920c 0x4b0 0xa34b 0x91ce 0x4c0 0xa549 0x9193 0x4d5 0xa747 0x9154 0x4f2 0xa945 0x910b 0x514 0xab43 0x90af 0x515 0xad40 0x907c 0x540 0xaf3e 0x905e 0x558 0xb13c 0x904b 0x57c 0xb33a 0x9035 0x5b0 0xb538 0x9019 0x604 0xb735 0x8fed 0x687 0xb933 0x8f7e 0x71c 0xbb31 0x8e2a 0x773 0xbd2f 0x8c2e 0x7e8 0xbf2d 0x8970 0x8e3 0xc12a 0x856c 0xb3e 0xc328 0x7e5b 0x1239 0xc526 0x7134 0x9ab>;
    battery1_profile_t3_num = <0x64>;
    battery1_profile_t3_col = <0x3>;
    battery1_profile_t3 = <0x0 0xace4 0x758 0x1fe 0xac5c 0x754 0x3fc 0xabdb 0x94e 0x5f9 0xab67 0xa36 0x7f7 0xaaf8 0xa2d 0x9f5 0xaa8c 0xa09 0xbf3 0xaa26 0x9f6 0xdf1 0xa9c0 0x9f6 0xfee 0xa94a 0x9ba 0x11ec 0xa8d3 0x99b 0x13ea 0xa861 0x992 0x15e8 0xa7ec 0x981 0x17e6 0xa76f 0x960 0x19e3 0xa6f8 0x960 0x1be1 0xa683 0x960 0x1ddf 0xa605 0x94e 0x1fdd 0xa585 0x939 0x21db 0xa50a 0x92e 0x23d8 0xa490 0x920 0x25d6 0xa412 0x8f9 0x27d4 0xa39b 0x8e4 0x29d2 0xa324 0x8e3 0x2bd0 0xa2ad 0x8c1 0x2dcd 0xa236 0x8b1 0x2fcb 0xa1bf 0x8a8 0x31c9 0xa14b 0x89e 0x33c7 0xa0dc 0x8b1 0x35c5 0xa065 0x8b1 0x37c2 0x9ff5 0x89e 0x39c0 0x9f87 0x8a8 0x3bbe 0x9f1d 0x8c9 0x3dbc 0x9eb4 0x8eb 0x3fba 0x9e46 0x900 0x41b7 0x9dd7 0x914 0x43b5 0x9d60 0x8ff 0x45b3 0x9cf0 0x8ea 0x47b1 0x9c87 0x8e3 0x49af 0x9c1d 0x8ce 0x4bac 0x9baf 0x8a3 0x4daa 0x9b40 0x879 0x4fa8 0x9ad2 0x84f 0x51a6 0x9a5d 0x811 0x53a4 0x99e7 0x7e1 0x55a1 0x9970 0x79e 0x579f 0x98fc 0x75a 0x599d 0x9892 0x735 0x5b9b 0x9835 0x720 0x5d99 0x97e0 0x70a 0x5f96 0x9792 0x708 0x6194 0x974c 0x708 0x6392 0x9708 0x708 0x6590 0x96c7 0x70f 0x678d 0x968c 0x721 0x698b 0x9650 0x721 0x6b89 0x961d 0x736 0x6d87 0x95ea 0x74b 0x6f85 0x95b7 0x753 0x7182 0x9584 0x753 0x7380 0x9554 0x759 0x757e 0x9529 0x76e 0x777c 0x94ff 0x784 0x797a 0x94d4 0x785 0x7b77 0x94b0 0x795 0x7d75 0x9489 0x79e 0x7f73 0x9462 0x7a7 0x8171 0x9440 0x7b7 0x836f 0x941f 0x7b8 0x856c 0x9405 0x7cd 0x876a 0x93ec 0x7e2 0x8968 0x93d3 0x7e9 0x8b66 0x93bd 0x7fe 0x8d64 0x93ac 0x822 0x8f61 0x939a 0x83a 0x915f 0x9381 0x865 0x935d 0x9367 0x87b 0x955b 0x9347 0x8a1 0x9759 0x9320 0x8be 0x9956 0x92f5 0x8dd 0x9b54 0x92c9 0x90d 0x9d52 0x9296 0x94e 0x9f50 0x9263 0x9a3 0xa14e 0x9220 0x9e5 0xa34b 0x91dc 0xa44 0xa549 0x919d 0xaba 0xa747 0x9158 0xb31 0xa945 0x9105 0xba4 0xab43 0x90b8 0xc39 0xad40 0x9074 0xce3 0xaf3e 0x9046 0xd9f 0xb13c 0x9027 0xe97 0xb33a 0x9005 0xfb6 0xb538 0x8fd8 0x1108 0xb735 0x8f9a 0x12b9 0xb933 0x8f1b 0x14a2 0xbb31 0x8e00 0x16c8 0xbd2f 0x8c3e 0x19bf 0xbf2d 0x89ca 0x1f04 0xc12a 0x864a 0x2a2c 0xc328 0x8152 0x3217 0xc526 0x7814 0x1b3f>;
    battery1_profile_t4_num = <0x64>;
    battery1_profile_t4_col = <0x3>;
    battery1_profile_t4 = <0x0 0xace4 0x125c 0x1fe 0xac29 0x125c 0x3fc 0xab91 0x126d 0x5f9 0xab0c 0x125a 0x7f7 0xaa90 0x1239 0x9f5 0xaa19 0x1249 0xbf3 0xa9a2 0x12a2 0xdf1 0xa92b 0x1278 0xfee 0xa8b4 0x124d 0x11ec 0xa83d 0x11f2 0x13ea 0xa7c6 0x1194 0x15e8 0xa750 0x113f 0x17e6 0xa6d7 0x10f9 0x19e3 0xa658 0x10e5 0x1be1 0xa5e3 0x10e5 0x1ddf 0xa56c 0x10d3 0x1fdd 0xa4ef 0x10cc 0x21db 0xa474 0x10b7 0x23d8 0xa3fd 0x109a 0x25d6 0xa386 0x1097 0x27d4 0xa30f 0x1082 0x29d2 0xa298 0x1058 0x2bd0 0xa228 0x104f 0x2dcd 0xa1b4 0x1035 0x2fcb 0xa13d 0x1001 0x31c9 0xa0c9 0xfb6 0x33c7 0xa05a 0xf60 0x35c5 0x9fec 0xfe0 0x37c2 0x9f85 0x1038 0x39c0 0x9f13 0x107e 0x3bbe 0x9e9c 0x10a6 0x3dbc 0x9e1e 0x10ab 0x3fba 0x9d98 0x1096 0x41b7 0x9d19 0x1080 0x43b5 0x9c99 0x1055 0x45b3 0x9c21 0x1019 0x47b1 0x9baa 0xfe7 0x49af 0x9b37 0xfc7 0x4bac 0x9acc 0xfb2 0x4daa 0x9a64 0xf97 0x4fa8 0x99f6 0xf57 0x51a6 0x9989 0xf69 0x53a4 0x9922 0xf6e 0x55a1 0x98bc 0xf61 0x579f 0x9859 0xf4c 0x599d 0x97fe 0xf46 0x5b9b 0x97a9 0xf6f 0x5d99 0x975d 0xf85 0x5f96 0x9710 0xf87 0x6194 0x96ca 0xf87 0x6392 0x9686 0xf92 0x6590 0x9645 0xfaf 0x678d 0x960a 0xfd2 0x698b 0x95ce 0xfd2 0x6b89 0x959b 0xfd2 0x6d87 0x9568 0xfe3 0x6f85 0x953b 0x1006 0x7182 0x9510 0x1027 0x7380 0x94e6 0x103c 0x757e 0x94bb 0x1051 0x777c 0x9491 0x1067 0x797a 0x946e 0x1090 0x7b77 0x9453 0x10ba 0x7d75 0x9439 0x10f1 0x7f73 0x9423 0x113a 0x8171 0x9410 0x1185 0x836f 0x93f8 0x11b3 0x856c 0x93ef 0x121d 0x876a 0x93d8 0x1273 0x8968 0x93bf 0x12c8 0x8b66 0x93a9 0x1332 0x8d64 0x9396 0x13b1 0x8f61 0x937b 0x142e 0x915f 0x9359 0x1498 0x935d 0x9337 0x152b 0x955b 0x9315 0x15e2 0x9759 0x92e9 0x16a1 0x9956 0x92b6 0x1760 0x9b54 0x9283 0x1825 0x9d52 0x924e 0x18fb 0x9f50 0x920a 0x19e5 0xa14e 0x91ce 0x1ae2 0xa34b 0x9186 0x1bd1 0xa549 0x913e 0x1cde 0xa747 0x90f7 0x1e10 0xa945 0x90ac 0x1f57 0xab43 0x9069 0x20c1 0xad40 0x9036 0x2255 0xaf3e 0x9003 0x2430 0xb13c 0x8fd5 0x268b 0xb33a 0x8f9e 0x297c 0xb538 0x8f50 0x2d17 0xb735 0x8eda 0x3182 0xb933 0x8e06 0x3712 0xbb31 0x8cb7 0x3ec9 0xbd2f 0x8b16 0x47e2 0xbf2d 0x88f1 0x452a 0xc12a 0x85a1 0x3d45 0xc328 0x84ee 0x3afc 0xc526 0x84ee 0x3afc>;
};

&battery_manager {
    charger = <&bq2589x_chg>;
};

&mtk_ctd {
    charger = <&bq2589x_chg>;
};

&extcon_usb {
    charger = <&bq2589x_chg>;
};

&charger {
    charger = <&bq2589x_chg>;
};

&pd_adapter {
    mi,non-mtk-pps-ctrl;
};

&i2c6 {
    mt6660: mt6660@34 {
        compatible = "mediatek,mt6660";
        #sound-dai-cells = <0x0>;
        reg = <0x34>;
        status = "disabled";
    };
};

&sound {
    mediatek,speaker-codec {
        sound-dai = <&mt6660>;
    };
};

&mtkheap_region_svp {
    status = "ok";
};

&mtkheap_region_wfd {
    status = "ok";
};

&mtee_svp {
    mtee: MTEE {
        compatible = "mediatek,mtk_svp_on_mtee_support";
    };
    svp: SecureVideoPath {
        compatible = "mediatek,mtk_sec_video_path_support";
    };
};

&memory_ssmr_features {
    svp-region-based-size = <0x0 0x18000000>;
    svp-page-based-size = <0x0 0x19000000>;
};

#include "sea/cust.dtsi"
#include "cust_mt6781_sea_camera.dtsi"
#include "cust_foursemi_audio.dtsi"
#include "cust_aw87xxx_audio.dtsi"
#include "touchscreen.dtsi"
#include "cust_mt6781_touch_1080x2300.dtsi"
#include "cust_mt6781_fingerprint.dtsi"
#include "bat_setting/mt6781_battery_table.dtsi"
